# max32630 register map
Vendor: Maxim Integrated; Series: max3263x; File version: 1.2
CPU: CM4 r0p1, little endian, no MPU, FPU, 3 interrupt priority bits
Registers are 32-bit, read-write, reset 0x0 unless marked. A register's access mark holds for its fields unless they carry their own. Offsets are from the block's base; [hi:lo] are bit positions.

## PWRSEQ — Power Sequencer
Base 0x40000A30
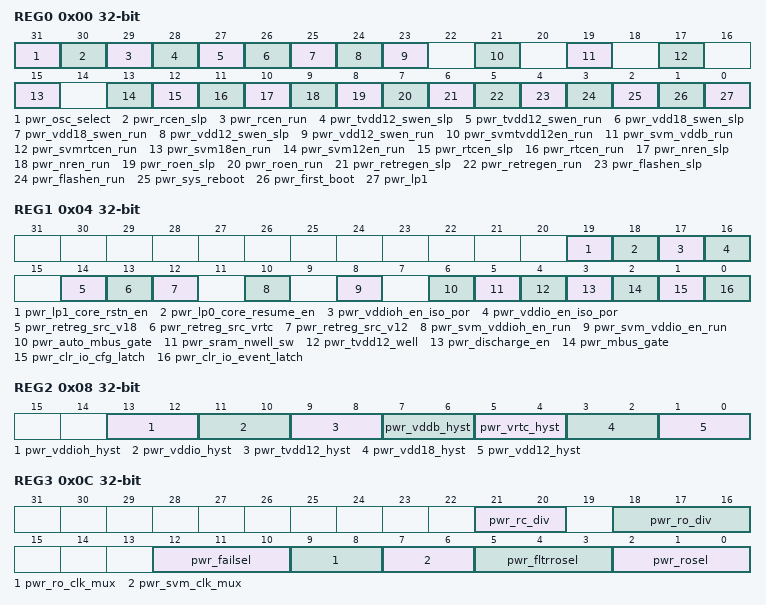
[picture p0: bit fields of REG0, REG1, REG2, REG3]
0x00 REG0 — Power Sequencer Control Register 0
  [31] pwr_osc_select — Selects main clock source - 96MHz RO or 4MHz RC.
  [30] pwr_rcen_slp — Enable 4MHz RC oscillator operation during Sleep Mode
  [29] pwr_rcen_run — Enable 4MHz RC oscillator operation during Run Mode
  [28] pwr_tvdd12_swen_slp — Enable TVDD12 power switch during Sleep Mode
  [27] pwr_tvdd12_swen_run — Enable TVDD12 power switch during Run Mode
  [26] pwr_vdd18_swen_slp — Enable VDD18 power switch during Sleep Mode
  [25] pwr_vdd18_swen_run — Enable VDD18 power switch during Run Mode
  [24] pwr_vdd12_swen_slp — Enable VDD12 power switch during Sleep Mode
  [23] pwr_vdd12_swen_run — Enable VDD12 power switch during Run Mode
  [21] pwr_svmtvdd12en_run — Enable TVDD12 SVM operation during Run Mode
  [19] pwr_svm_vddb_run — Enable VDDB SVM operation during Run Mode
  [17] pwr_svmrtcen_run — Enable VRTC SVM operation during Run Mode
  [15] pwr_svm18en_run — Enable VDD18_SW SVM operation during Run Mode
  [13] pwr_svm12en_run — Enable VDD12_SW SVM operation during Run Mode
  [12] pwr_rtcen_slp — Enable Real Time Clock Operation during Sleep Mode
  [11] pwr_rtcen_run — Enable Real Time Clock Operation during Run Mode
  [10] pwr_nren_slp — Enable Nano Oscillator in Sleep Mode
  [9] pwr_nren_run — Enable Nano Oscillator in Run Mode
  [8] pwr_roen_slp — Enable 96MHz System Relaxation Oscillator in Sleep Mode
  [7] pwr_roen_run — Enable 96MHz System Relaxation Oscillator in Run Mode
  [6] pwr_retregen_slp — Enable Retention Regulator Operation during Sleep Mode
  [5] pwr_retregen_run — Enable Retention Regulator Operation during Run Mode
  [4] pwr_flashen_slp — Enable Flash Operation during Sleep Mode
  [3] pwr_flashen_run — Enable Flash Operation during Run Mode
  [2] pwr_sys_reboot wo — Firmware System Reboot Request
  [1] pwr_first_boot — Wake on First Boot
  [0] pwr_lp1 — Shutdown Power Mode Select
0x04 REG1 — Power Sequencer Control Register 1
  [19] pwr_lp1_core_rstn_en — Enables Core RSTN to Toggle during LP1
  [18] pwr_lp0_core_resume_en — Enables Core Resume to Toggle during LP0
  [17] pwr_vddioh_en_iso_por — Enables VDDIOH Isolation POR
  [16] pwr_vddio_en_iso_por — Enables VDDIO Isolation POR
  [14] pwr_retreg_src_v18 — Enables VDD18 Rail as Retention Power Supply
  [13] pwr_retreg_src_vrtc — Enables VRTC Rail as Retention Power Supply
  [12] pwr_retreg_src_v12 — Enables VDD12 Rail as Retention Power Supply
  [10] pwr_svm_vddioh_en_run — Enables SVM for VDDIOH_SW during Run Mode
  [8] pwr_svm_vddio_en_run — Enables SVM for VDDIO_SW during Run Mode
  [6] pwr_auto_mbus_gate — Automatically Set/Clear GPIO MBus Gate
  [5] pwr_sram_nwell_sw — SRAM/Cache Well Switch
  [4] pwr_tvdd12_well — TVDD12 Well Switch
  [3] pwr_discharge_en — Enable Flash Discharge During Powerfail Event
  [2] pwr_mbus_gate — Freeze GPIO MBus State
  [1] pwr_clr_io_cfg_latch — Clear all GPIO Configuration Latches
  [0] pwr_clr_io_event_latch — Clear all GPIO Event Seen Latches
0x08 REG2 — Power Sequencer Control Register 2
  [13:12] pwr_vddioh_hyst — VDDIOH Comparator Hysteresis Setting
  [11:10] pwr_vddio_hyst — VDDIO Comparator Hysteresis Setting
  [9:8] pwr_tvdd12_hyst — TVDD12 Comparator Hysteresis Setting
  [7:6] pwr_vddb_hyst — VDDB Comparator Hysteresis Setting
  [5:4] pwr_vrtc_hyst — VRTC Comparator Hysteresis Setting
  [3:2] pwr_vdd18_hyst — VDD18_SW Comparator Hysteresis Setting
  [1:0] pwr_vdd12_hyst — VDD12_SW Comparator Hysteresis Setting
0x0C REG3 — Power Sequencer Control Register 3
  [21:20] pwr_rc_div — Frequency Divider for 4MHz RC Oscillator
  [18:16] pwr_ro_div — Frequency Divider for 96MHz Relaxation Oscillator
  [12:10] pwr_failsel — Timeout before rebooting during PowerFail/BootFail events.
  [9:8] pwr_ro_clk_mux — Relaxation Clock Mux
  [7:6] pwr_svm_clk_mux — SVM Clock Mux
  [5:3] pwr_fltrrosel — Power Supply Filter Timeout for Wakeup
  [2:0] pwr_rosel — Relaxation Oscillator Stable Timeout for Wakeup
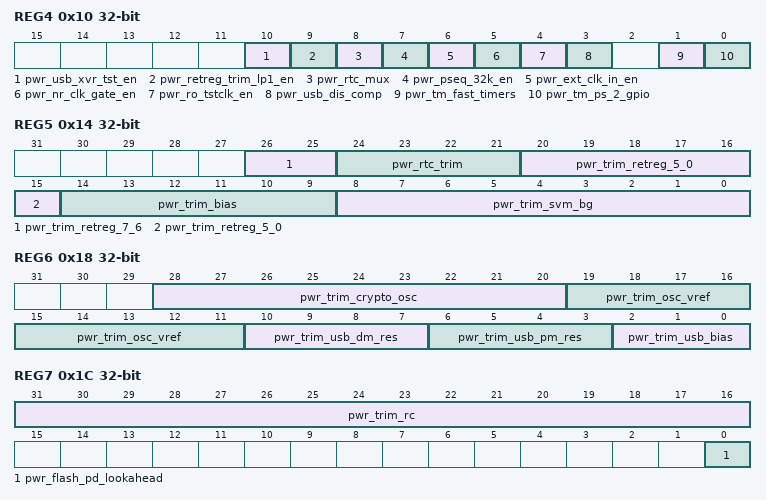
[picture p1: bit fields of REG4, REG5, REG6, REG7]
0x10 REG4 — Power Sequencer Control Register 4 (Internal Test Only)
  [10] pwr_usb_xvr_tst_en — Internal Use Only
  [9] pwr_retreg_trim_lp1_en — Internal Use Only
  [8] pwr_rtc_mux — Internal Use Only
  [7] pwr_pseq_32k_en — Internal Use Only
  [6] pwr_ext_clk_in_en — Internal Use Only
  [5] pwr_nr_clk_gate_en — Internal Use Only
  [4] pwr_ro_tstclk_en — Internal Use Only
  [3] pwr_usb_dis_comp — Internal Use Only
  [1] pwr_tm_fast_timers — Internal Use Only
  [0] pwr_tm_ps_2_gpio — Internal Use Only
0x14 REG5 — Power Sequencer Control Register 5 (Trim 0)
  [26:25] pwr_trim_retreg_7_6 — Retention Regulator Trim Setting (Bits 7:6)
  [24:21] pwr_rtc_trim — Real Time Clock Trim Setting
  [20:15] pwr_trim_retreg_5_0 — Retention Regulator Trim Setting (Bits 5:0)
  [14:9] pwr_trim_bias — Power Manager Bias Current Trim Setting
  [8:0] pwr_trim_svm_bg — Power Manager Bandgap Trim Setting
0x18 REG6 — Power Sequencer Control Register 6 (Trim 1)
  [28:20] pwr_trim_crypto_osc — Crypto Oscillator Trim Setting
  [19:11] pwr_trim_osc_vref — Relaxation Oscillator Trim Setting
  [10:7] pwr_trim_usb_dm_res — USB Data Minus Slew Rate Trim Setting
  [6:3] pwr_trim_usb_pm_res — USB Data Plus Slew Rate Trim Setting
  [2:0] pwr_trim_usb_bias — USB Bias Current Trim Setting
0x1C REG7 — Power Sequencer Control Register 7 (Trim 2)
  [31:16] pwr_trim_rc — Trim Setting for 4MHz Internal RC Oscillator
  [0] pwr_flash_pd_lookahead ro — Flash Powerdown Lookahead Flag
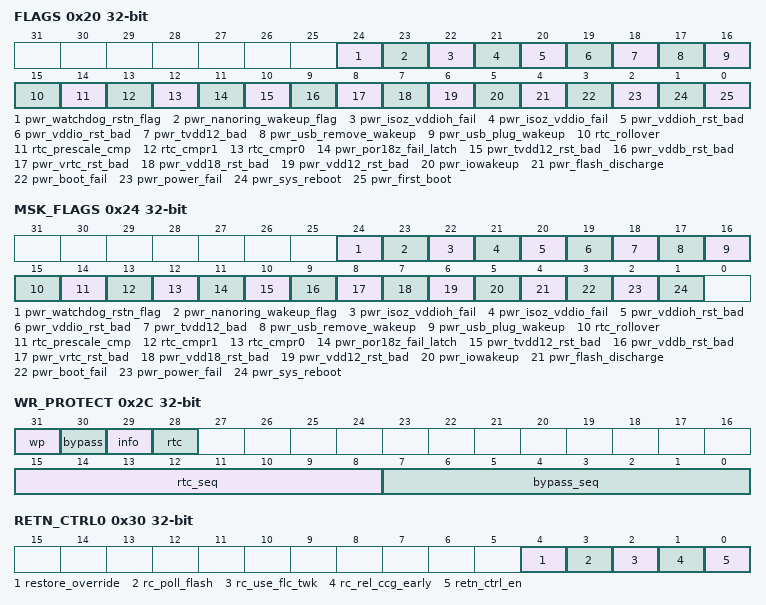
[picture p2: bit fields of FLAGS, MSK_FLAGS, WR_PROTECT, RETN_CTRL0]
0x20 FLAGS — Power Sequencer Flags
  [24] pwr_watchdog_rstn_flag write-1-clears — Power Sequencer Reset Triggered by WDT2 Flag
  [23] pwr_nanoring_wakeup_flag write-1-clears — Wakeup Triggered by WDT2 Flag
  [22] pwr_isoz_vddioh_fail write-1-clears — VDDIOH Isolation POR Tripped
  [21] pwr_isoz_vddio_fail write-1-clears — VDDIO Isolation POR Tripped
  [20] pwr_vddioh_rst_bad write-1-clears — VDDIOH Comparator Tripped
  [19] pwr_vddio_rst_bad write-1-clears — VDDIO Comparator Tripped
  [18] pwr_tvdd12_bad write-1-clears — Retention Regulator POR Tripped Event Detected Flag
  [17] pwr_usb_remove_wakeup write-1-clears — USB Power Remove Wakeup Event Detected Flag
  [16] pwr_usb_plug_wakeup write-1-clears — USB Power Connect Wakeup Event Detected Flag
  [15] rtc_rollover ro — RTC Rollover Event Detected Flag
  [14] rtc_prescale_cmp ro — RTC Prescale Comparator Match Event Detected Flag
  [13] rtc_cmpr1 ro — RTC Comparator 1 Match Event Detected Flag
  [12] rtc_cmpr0 ro — RTC Comparator 0 Match Event Detected Flag
  [11] pwr_por18z_fail_latch write-1-clears — POR18 and POR18_bg have been tripped
  [10] pwr_tvdd12_rst_bad write-1-clears — TVDD12 Comparator Tripped Event Detected Flag
  [9] pwr_vddb_rst_bad write-1-clears — VDDB Comparator Tripped Event Detected Flag
  [8] pwr_vrtc_rst_bad write-1-clears — VRTC Comparator Tripped Event Detected Flag
  [7] pwr_vdd18_rst_bad write-1-clears — VDD18_SW Comparator Tripped Event Detected Flag
  [6] pwr_vdd12_rst_bad write-1-clears — VDD12_SW Comparator Tripped Event Detected Flag
  [5] pwr_iowakeup write-1-clears — GPIO Wakeup Event Detected Flag
  [4] pwr_flash_discharge write-1-clears — Flash Discharged During Powerfail Event Detected Flag
  [3] pwr_boot_fail write-1-clears — Boot Fail Event Detected Flag
  [2] pwr_power_fail write-1-clears — Power Fail Event Detected Flag
  [1] pwr_sys_reboot ro — Firmware Reset Event Detected Flag
  [0] pwr_first_boot ro — Initial Boot Event Detected Flag
0x24 MSK_FLAGS — Power Sequencer Flags Mask Register
  [24] pwr_watchdog_rstn_flag — Mask for WDT2 PWRSEQ Reset (Internal RSTN) Event
  [23] pwr_nanoring_wakeup_flag — Mask for WDT2 Wakeup Event
  [22] pwr_isoz_vddioh_fail — Mask for VDDIOH Isolation POR
  [21] pwr_isoz_vddio_fail — Mask for VDDIO Isolation POR
  [20] pwr_vddioh_rst_bad — Mask for VDDIOH Comparator
  [19] pwr_vddio_rst_bad — Mask for VDDIO Comparator
  [18] pwr_tvdd12_bad — Mask for TVDD12 power fail event
  [17] pwr_usb_remove_wakeup — Mask for USB plug disconnect event
  [16] pwr_usb_plug_wakeup — Mask for USB plug connect event
  [15] rtc_rollover — Mask for RTC rollover event
  [14] rtc_prescale_cmp — Mask for RTC prescale compare event
  [13] rtc_cmpr1 — Mask for RTC compare 1 event
  [12] rtc_cmpr0 — Mask for RTC compare 0 event
  [11] pwr_por18z_fail_latch — Mask for POR18 powerfail event
  [10] pwr_tvdd12_rst_bad — Mask for TVDD12 rst event
  [9] pwr_vddb_rst_bad — Mask for VDDB rst event
  [8] pwr_vrtc_rst_bad — Mask for VRTC rst event
  [7] pwr_vdd18_rst_bad — Mask for VDD18 rst event
  [6] pwr_vdd12_rst_bad — Mask for VDD12 rst event
  [5] pwr_iowakeup — Mask for GPIO wakeup event detect
  [4] pwr_flash_discharge — Mask for flash discharge event
  [3] pwr_boot_fail — Mask for previous boot fail detect
  [2] pwr_power_fail — Mask for previous power fail detect
  [1] pwr_sys_reboot — Mask for system reboot detect
0x2C WR_PROTECT — Critical Setting Write Protect Register
  [31] wp ro — Critical Setting Write Protect
  [30] bypass ro — Write Protect Bypass
  [29] info ro — Write Protect from Info Block
  [28] rtc ro — Write Protect from RTC
  [15:8] rtc_seq wo — Write Protect RTC Sequence Write
  [7:0] bypass_seq wo — Write Protect Bypass Sequence Write
0x30 RETN_CTRL0 — Retention Control Register 0
  [4] restore_override — Restore Override (Reserved).
  [3] rc_poll_flash — Enable Automatic Flash Polling for Wakeup
  [2] rc_use_flc_twk — Enable Flash Controller TWake Timer
  [1] rc_rel_ccg_early — Early Core Clock Gate Release
  [0] retn_ctrl_en — Retention Controller Enable
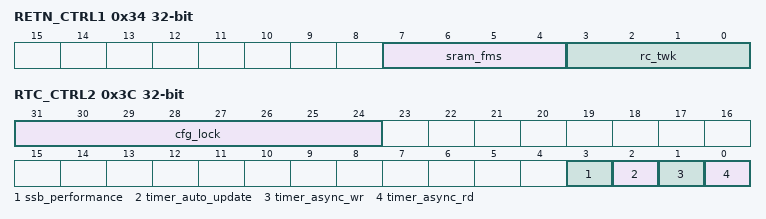
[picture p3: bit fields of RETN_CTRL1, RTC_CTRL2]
0x34 RETN_CTRL1 — Retention Control Register 1
  [7:4] sram_fms — SRAM Margin Setting (Reserved).
  [3:0] rc_twk — Retention Controller TWake Cycle Count
0x38 PWR_MISC — Power Misc Controls
  [0] invert_4_mask_bits — Invert Sense of Power Mask Flags for RTC
0x3C RTC_CTRL2 — RTC Misc Controls
  [31:24] cfg_lock, [3] ssb_performance, [2] timer_auto_update, [1] timer_async_wr, [0] timer_async_rd
